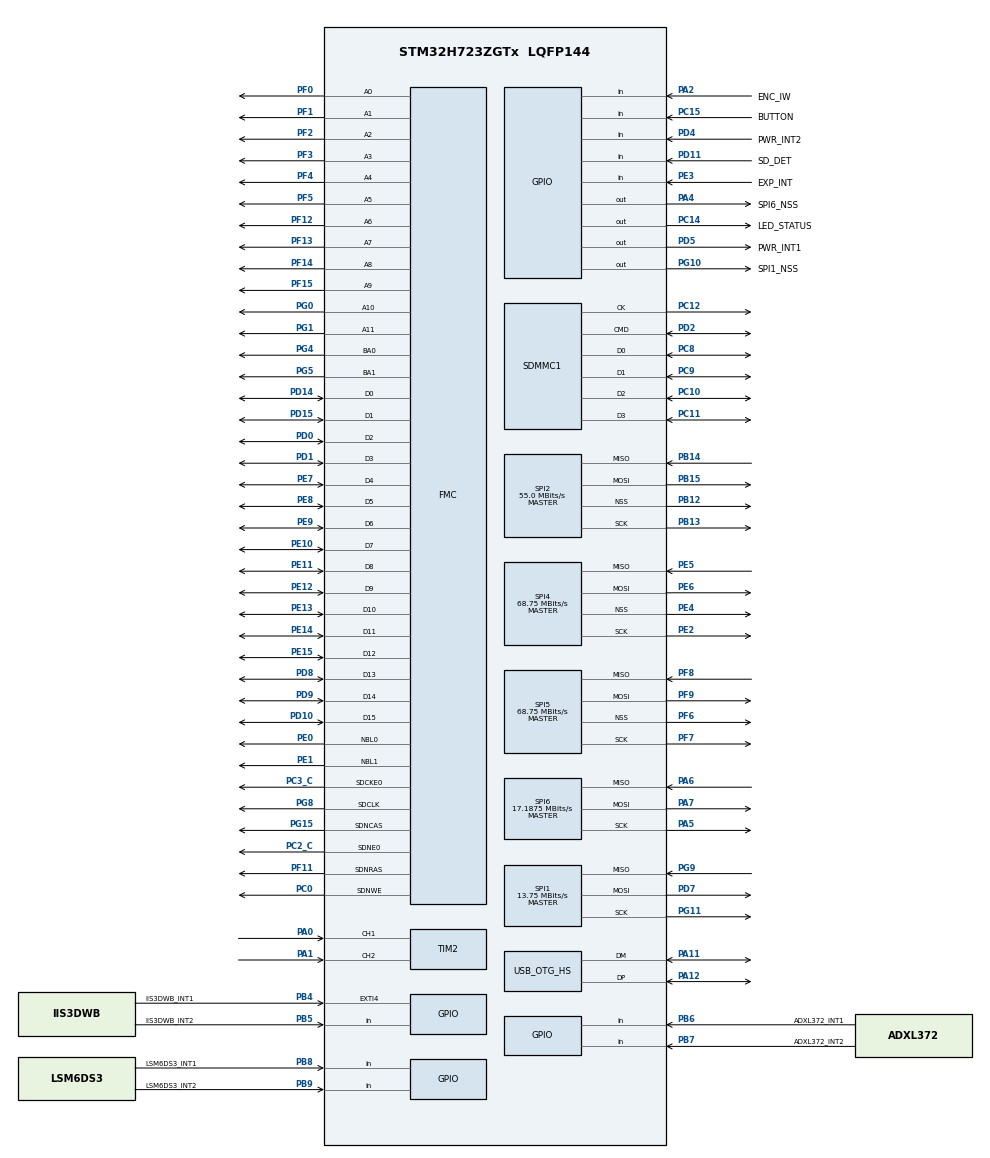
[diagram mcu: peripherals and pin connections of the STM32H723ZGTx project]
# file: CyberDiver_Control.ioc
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FATFS.BSP.number=1
FATFS.USE_DMA_CODE_SD=1
FATFS0.BSP.STBoard=false
FATFS0.BSP.api=Unknown
FATFS0.BSP.instance=PD11
FATFS0.BSP.ip=GPIO
FATFS0.BSP.mode=Input
FATFS0.BSP.name=Detect_SDIO
FATFS0.BSP.solution=PD11
FMC.CASLatency1=FMC_SDRAM_CAS_LATENCY_2
FMC.ColumnBitsNumber1=FMC_SDRAM_COLUMN_BITS_NUM_9
FMC.ExitSelfRefreshDelay1=8
FMC.LoadToActiveDelay1=2
FMC.RCDDelay1=2
FMC.RPDelay1=2
FMC.RPDelay2=2
FMC.ReadBurst1=FMC_SDRAM_RBURST_ENABLE
FMC.ReadBurst2=FMC_SDRAM_RBURST_ENABLE
FMC.ReadPipeDelay1=FMC_SDRAM_RPIPE_DELAY_2
FMC.ReadPipeDelay2=FMC_SDRAM_RPIPE_DELAY_2
FMC.RowCycleDelay1=6
FMC.RowCycleDelay2=6
FMC.SDClockPeriod1=FMC_SDRAM_CLOCK_PERIOD_2
FMC.SDClockPeriod2=FMC_SDRAM_CLOCK_PERIOD_2
FMC.SelfRefreshTime1=5
FMC.WriteRecoveryTime1=3
Mcu.Family=STM32H7
Mcu.Name=STM32H723ZGTx
Mcu.Package=LQFP144
NVIC.EXTI4_IRQn=true\:1\:1\:true\:false\:true\:true\:true\:false
NVIC.OTG_HS_EP1_IN_IRQn=true\:1\:1\:true\:false\:true\:true\:true\:true
NVIC.OTG_HS_EP1_OUT_IRQn=true\:1\:1\:true\:false\:true\:true\:true\:true
NVIC.OTG_HS_IRQn=true\:1\:1\:true\:false\:true\:false\:true\:true
NVIC.PriorityGroup=NVIC_PRIORITYGROUP_2
NVIC.SDMMC1_IRQn=true\:2\:2\:true\:false\:true\:true\:true\:true
NVIC.TIM3_IRQn=true\:0\:0\:false\:false\:true\:true\:true\:true
PA0.Signal=S_TIM2_CH1_ETR
PA1.Signal=S_TIM2_CH2
PA11.Mode=Device_Only_FS
PA11.Signal=USB_OTG_HS_DM
PA12.Mode=Device_Only_FS
PA12.Signal=USB_OTG_HS_DP
PA13(JTMS/SWDIO).Mode=Trace_Asynchronous_SW
PA13(JTMS/SWDIO).Signal=DEBUG_JTMS-SWDIO
PA14(JTCK/SWCLK).Mode=Trace_Asynchronous_SW
PA14(JTCK/SWCLK).Signal=DEBUG_JTCK-SWCLK
PA2.GPIO_Label=ENC_IW
PA2.Signal=GPIO_Input
PA4.GPIO_Label=SPI6_NSS
PA4.GPIO_Speed=GPIO_SPEED_FREQ_VERY_HIGH
PA4.PinState=GPIO_PIN_SET
PA4.Signal=GPIO_Output
PA5.Mode=Full_Duplex_Master
PA5.Signal=SPI6_SCK
PA6.Mode=Full_Duplex_Master
PA6.Signal=SPI6_MISO
PA7.Mode=Full_Duplex_Master
PA7.Signal=SPI6_MOSI
PB12.Mode=NSS_Signal_Hard_Output
PB12.Signal=SPI2_NSS
PB13.Mode=Full_Duplex_Master
PB13.Signal=SPI2_SCK
PB14.Mode=Full_Duplex_Master
PB14.Signal=SPI2_MISO
PB15.Mode=Full_Duplex_Master
PB15.Signal=SPI2_MOSI
PB3(JTDO/TRACESWO).Mode=Trace_Asynchronous_SW
PB3(JTDO/TRACESWO).Signal=DEBUG_JTDO-SWO
PB4(NJTRST).GPIO_Label=IIS3DWB_INT1
PB4(NJTRST).Signal=GPXTI4
PB5.GPIO_Label=IIS3DWB_INT2
PB5.Signal=GPIO_Input
PB6.GPIO_Label=ADXL372_INT1
PB6.Signal=GPIO_Input
PB7.GPIO_Label=ADXL372_INT2
PB7.Signal=GPIO_Input
PB8.GPIO_Label=LSM6DS3_INT1
PB8.Signal=GPIO_Input
PB9.GPIO_Label=LSM6DS3_INT2
PB9.Signal=GPIO_Input
PC0.Signal=FMC_SDNWE
PC10.Mode=SD_4_bits_Wide_bus
PC10.Signal=SDMMC1_D2
PC11.Mode=SD_4_bits_Wide_bus
PC11.Signal=SDMMC1_D3
PC12.Mode=SD_4_bits_Wide_bus
PC12.Signal=SDMMC1_CK
PC14-OSC32_IN.GPIO_Label=LED_STATUS
PC14-OSC32_IN.Signal=GPIO_Output
PC15-OSC32_OUT.GPIO_Label=BUTTON
PC15-OSC32_OUT.Signal=GPIO_Input
PC2_C.Mode=SdramChipSelect1_1
PC2_C.Signal=FMC_SDNE0
PC3_C.Mode=SdramChipSelect1_1
PC3_C.Signal=FMC_SDCKE0
PC8.Mode=SD_4_bits_Wide_bus
PC8.Signal=SDMMC1_D0
PC9.Mode=SD_4_bits_Wide_bus
PC9.Signal=SDMMC1_D1
PD0.Signal=FMC_D2_DA2
PD1.Signal=FMC_D3_DA3
PD10.Signal=FMC_D15_DA15
PD11.GPIO_Label=SD_DET
PD11.Signal=GPIO_Input
PD14.Signal=FMC_D0_DA0
PD15.Signal=FMC_D1_DA1
PD2.Mode=SD_4_bits_Wide_bus
PD2.Signal=SDMMC1_CMD
PD4.GPIO_Label=PWR_INT2
PD4.Signal=GPIO_Input
PD5.GPIO_Label=PWR_INT1
PD5.GPIO_Speed=GPIO_SPEED_FREQ_VERY_HIGH
PD5.Signal=GPIO_Output
PD7.Mode=Full_Duplex_Master
PD7.Signal=SPI1_MOSI
PD8.Signal=FMC_D13_DA13
PD9.Signal=FMC_D14_DA14
PE0.Signal=FMC_NBL0
PE1.Signal=FMC_NBL1
PE10.Signal=FMC_D7_DA7
PE11.Signal=FMC_D8_DA8
PE12.Signal=FMC_D9_DA9
PE13.Signal=FMC_D10_DA10
PE14.Signal=FMC_D11_DA11
PE15.Signal=FMC_D12_DA12
PE2.Mode=Full_Duplex_Master
PE2.Signal=SPI4_SCK
PE3.GPIO_Label=EXP_INT
PE3.Signal=GPIO_Input
PE4.Mode=NSS_Signal_Hard_Output
PE4.Signal=SPI4_NSS
PE5.Mode=Full_Duplex_Master
PE5.Signal=SPI4_MISO
PE6.Mode=Full_Duplex_Master
PE6.Signal=SPI4_MOSI
PE7.Signal=FMC_D4_DA4
PE8.Signal=FMC_D5_DA5
PE9.Signal=FMC_D6_DA6
PF0.Signal=FMC_A0
PF1.Signal=FMC_A1
PF11.Signal=FMC_SDNRAS
PF12.Signal=FMC_A6
PF13.Signal=FMC_A7
PF14.Signal=FMC_A8
PF15.Signal=FMC_A9
PF2.Signal=FMC_A2
PF3.Signal=FMC_A3
PF4.Signal=FMC_A4
PF5.Signal=FMC_A5
PF6.Mode=NSS_Signal_Hard_Output
PF6.Signal=SPI5_NSS
PF7.Mode=Full_Duplex_Master
PF7.Signal=SPI5_SCK
PF8.Mode=Full_Duplex_Master
PF8.Signal=SPI5_MISO
PF9.Mode=Full_Duplex_Master
PF9.Signal=SPI5_MOSI
PG0.Signal=FMC_A10
PG1.Signal=FMC_A11
PG10.GPIO_Label=SPI1_NSS
PG10.GPIO_Speed=GPIO_SPEED_FREQ_VERY_HIGH
PG10.PinState=GPIO_PIN_SET
PG10.Signal=GPIO_Output
PG11.Mode=Full_Duplex_Master
PG11.Signal=SPI1_SCK
PG15.Signal=FMC_SDNCAS
PG4.Signal=FMC_A14_BA0
PG5.Signal=FMC_A15_BA1
PG8.Signal=FMC_SDCLK
PG9.Mode=Full_Duplex_Master
PG9.Signal=SPI1_MISO
PH0-OSC_IN.Mode=HSE-External-Oscillator
PH0-OSC_IN.Signal=RCC_OSC_IN
PH1-OSC_OUT.Mode=HSE-External-Oscillator
PH1-OSC_OUT.Signal=RCC_OSC_OUT
ProjectManager.HeapSize=0x400
ProjectManager.StackSize=0x800
ProjectManager.TargetToolchain=STM32CubeIDE
RCC.ADCFreq_Value=200000000
RCC.APB1Freq_Value=137500000
RCC.APB2Freq_Value=137500000
RCC.APB3Freq_Value=137500000
RCC.APB4Freq_Value=137500000
RCC.CortexFreq_Value=550000000
RCC.D1PPRE=RCC_APB3_DIV2
RCC.D2PPRE1=RCC_APB1_DIV2
RCC.D2PPRE2=RCC_APB2_DIV2
RCC.D3PPRE=RCC_APB4_DIV2
RCC.DIVM1=3
RCC.DIVM2=12
RCC.DIVN1=68
RCC.DIVN2=200
RCC.DIVP1=1
RCC.DIVQ1=5
RCC.FMCCLockSelection=RCC_FMCCLKSOURCE_PLL2
RCC.HCLKFreq_Value=275000000
RCC.HPRE=RCC_HCLK_DIV2
RCC.HSE_VALUE=24000000
RCC.PLL2FRACN=0
RCC.PLL3FRACN=0
RCC.PLLFRACN=6144
RCC.PLLSourceVirtual=RCC_PLLSOURCE_HSE
RCC.SYSCLKFreq_VALUE=550000000
RCC.SYSCLKSource=RCC_SYSCLKSOURCE_PLLCLK
RCC.USBCLockSelection=RCC_USBCLKSOURCE_HSI48
RCC.USBFreq_Value=48000000
SDMMC1.ClockDiv=4
SH.FMC_A0.0=FMC_A0,12b-sda1
SH.FMC_A1.0=FMC_A1,12b-sda1
SH.FMC_A10.0=FMC_A10,12b-sda1
SH.FMC_A11.0=FMC_A11,12b-sda1
SH.FMC_A14_BA0.0=FMC_BA0,FourSdramBanks1
SH.FMC_A15_BA1.0=FMC_BA1,FourSdramBanks1
SH.FMC_A2.0=FMC_A2,12b-sda1
SH.FMC_A3.0=FMC_A3,12b-sda1
SH.FMC_A4.0=FMC_A4,12b-sda1
SH.FMC_A5.0=FMC_A5,12b-sda1
SH.FMC_A6.0=FMC_A6,12b-sda1
SH.FMC_A7.0=FMC_A7,12b-sda1
SH.FMC_A8.0=FMC_A8,12b-sda1
SH.FMC_A9.0=FMC_A9,12b-sda1
SH.FMC_D0_DA0.0=FMC_D0,sd-16b-d1
SH.FMC_D10_DA10.0=FMC_D10,sd-16b-d1
SH.FMC_D11_DA11.0=FMC_D11,sd-16b-d1
SH.FMC_D12_DA12.0=FMC_D12,sd-16b-d1
SH.FMC_D13_DA13.0=FMC_D13,sd-16b-d1
SH.FMC_D14_DA14.0=FMC_D14,sd-16b-d1
SH.FMC_D15_DA15.0=FMC_D15,sd-16b-d1
SH.FMC_D1_DA1.0=FMC_D1,sd-16b-d1
SH.FMC_D2_DA2.0=FMC_D2,sd-16b-d1
SH.FMC_D3_DA3.0=FMC_D3,sd-16b-d1
SH.FMC_D4_DA4.0=FMC_D4,sd-16b-d1
SH.FMC_D5_DA5.0=FMC_D5,sd-16b-d1
SH.FMC_D6_DA6.0=FMC_D6,sd-16b-d1
SH.FMC_D7_DA7.0=FMC_D7,sd-16b-d1
SH.FMC_D8_DA8.0=FMC_D8,sd-16b-d1
SH.FMC_D9_DA9.0=FMC_D9,sd-16b-d1
SH.FMC_NBL0.0=FMC_NBL0,Sd2ByteEnable1
SH.FMC_NBL1.0=FMC_NBL1,Sd2ByteEnable1
SH.FMC_SDCLK.0=FMC_SDCLK,12b-sda1
SH.FMC_SDNCAS.0=FMC_SDNCAS,12b-sda1
SH.FMC_SDNRAS.0=FMC_SDNRAS,12b-sda1
SH.FMC_SDNWE.0=FMC_SDNWE,12b-sda1
SH.S_TIM2_CH1_ETR.0=TIM2_CH1,Encoder_Interface
SH.S_TIM2_CH2.0=TIM2_CH2,Encoder_Interface
SPI1.BaudRatePrescaler=SPI_BAUDRATEPRESCALER_8
SPI1.CalculateBaudRate=13.75 MBits/s
SPI1.DataSize=SPI_DATASIZE_8BIT
SPI1.Direction=SPI_DIRECTION_2LINES
SPI1.Mode=SPI_MODE_MASTER
SPI1.NSSPMode=SPI_NSS_PULSE_DISABLE
SPI1.VirtualType=VM_MASTER
SPI2.CalculateBaudRate=55.0 MBits/s
SPI2.Direction=SPI_DIRECTION_2LINES
SPI2.Mode=SPI_MODE_MASTER
SPI2.VirtualNSS=VM_NSSHARD
SPI2.VirtualType=VM_MASTER
SPI4.BaudRatePrescaler=SPI_BAUDRATEPRESCALER_2
SPI4.CalculateBaudRate=68.75 MBits/s
SPI4.Direction=SPI_DIRECTION_2LINES
SPI4.Mode=SPI_MODE_MASTER
SPI4.VirtualNSS=VM_NSSHARD
SPI4.VirtualType=VM_MASTER
SPI5.CalculateBaudRate=68.75 MBits/s
SPI5.Direction=SPI_DIRECTION_2LINES
SPI5.Mode=SPI_MODE_MASTER
SPI5.VirtualNSS=VM_NSSHARD
SPI5.VirtualType=VM_MASTER
SPI6.BaudRatePrescaler=SPI_BAUDRATEPRESCALER_8
SPI6.CalculateBaudRate=17.1875 MBits/s
SPI6.DataSize=SPI_DATASIZE_8BIT
SPI6.Direction=SPI_DIRECTION_2LINES
SPI6.Mode=SPI_MODE_MASTER
SPI6.NSSPMode=SPI_NSS_PULSE_DISABLE
SPI6.VirtualType=VM_MASTER
TIM2.EncoderMode=TIM_ENCODERMODE_TI12
TIM3.Period=99
TIM3.Prescaler=274
TIM5.Prescaler=274
USB_DEVICE.CLASS_NAME_HS=CDC
USB_DEVICE.PRODUCT_STRING_CDC_HS=CyberDiver
USB_DEVICE.USBD_LPM_ENABLED=0
USB_DEVICE.USBD_SELF_POWERED=0
USB_DEVICE.VirtualMode=Cdc
USB_DEVICE.VirtualModeHS=Cdc_HS
USB_OTG_HS.VirtualMode-Device_Only_FS=Device_Only_FS
VP_FATFS_VS_SDIO.Mode=SDIO
VP_MEMORYMAP_VS_MEMORYMAP.Mode=CurAppReg
VP_TIM3_VS_ClockSourceINT.Mode=Internal
VP_TIM5_VS_ClockSourceINT.Mode=Internal
VP_USB_DEVICE_VS_USB_DEVICE_CDC_HS.Mode=CDC_HS
board=custom

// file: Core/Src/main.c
/* USER CODE BEGIN Header */
/**
  ******************************************************************************
  * @file           : main.c
  * @brief          : Main program body
  ******************************************************************************
  * @attention
  *
  * Copyright (c) 2024 STMicroelectronics.
  * All rights reserved.
  *
  * This software is licensed under terms that can be found in the LICENSE file
  * in the root directory of this software component.
  * If no LICENSE file comes with this software, it is provided AS-IS.
  *
  ******************************************************************************
  */
/* USER CODE END Header */
#include "main.h"
#include "fatfs.h"
#include "usb_device.h"

/* USER CODE BEGIN Includes */
#include "cyber_diver.h"
/* USER CODE END Includes */

SD_HandleTypeDef hsd1;

SPI_HandleTypeDef hspi1;
SPI_HandleTypeDef hspi2;
SPI_HandleTypeDef hspi4;
SPI_HandleTypeDef hspi5;
SPI_HandleTypeDef hspi6;

TIM_HandleTypeDef htim2;
TIM_HandleTypeDef htim3;
TIM_HandleTypeDef htim5;

SDRAM_HandleTypeDef hsdram1;

/* USER CODE BEGIN PV */
CyberDiver cd;
/* USER CODE END PV */

void SystemClock_Config(void);
static void MX_GPIO_Init(void);
static void MX_FMC_Init(void);
static void MX_SPI1_Init(void);
static void MX_SPI2_Init(void);
static void MX_SPI4_Init(void);
static void MX_SPI5_Init(void);
static void MX_SPI6_Init(void);
static void MX_TIM2_Init(void);
static void MX_TIM5_Init(void);
static void MX_TIM3_Init(void);
static void MX_SDMMC1_SD_Init(void);

/* USER CODE BEGIN 0 */

void FMC_Init()
{
	/*
	 * This SDRAM initialization code comes from the following ST support article:
	 * https://community.st.com/t5/stm32-mcus/how-to-set-up-the-fmc-peripheral-to-interface-with-the-sdram/ta-p/49457
	 */

	FMC_SDRAM_CommandTypeDef Command;
	HAL_StatusTypeDef status;
	(void)status;

	/* Step 1 and Step 2 already done in HAL_SDRAM_Init() */

	/* Step 3: Configure a clock configuration enable command */
	Command.CommandMode            = FMC_SDRAM_CMD_CLK_ENABLE;  /* Set MODE bits to "001" */
	Command.CommandTarget          = FMC_SDRAM_CMD_TARGET_BANK1;  /* configure the Target Bank bits */
	Command.AutoRefreshNumber      = 1;
	Command.ModeRegisterDefinition = 0;
	status = HAL_SDRAM_SendCommand(&hsdram1, &Command, 0xfff);

	/* Step 4: Insert 100 us minimum delay - Min HAL Delay is 1ms */
	HAL_Delay(1);

	/* Step 5: Configure a PALL (precharge all) command */
	Command.CommandMode            = FMC_SDRAM_CMD_PALL;  /* Set MODE bits to "010" */
	status = HAL_SDRAM_SendCommand(&hsdram1, &Command, 0xfff);

	/* Step 6: Configure an Auto Refresh command */
	Command.CommandMode            = FMC_SDRAM_CMD_AUTOREFRESH_MODE;  /* Set MODE bits to "011" */
	Command.AutoRefreshNumber      = 2;
	status = HAL_SDRAM_SendCommand(&hsdram1, &Command, 0xfff);

	/* Step 7: Program the external memory mode register */
	Command.CommandMode            = FMC_SDRAM_CMD_LOAD_MODE;  /*set the MODE bits to "100" */
	Command.ModeRegisterDefinition =  (uint32_t)0 | 0<<3 | 2<<4 | 0<<7 | 1<<9;
	status = HAL_SDRAM_SendCommand(&hsdram1, &Command, 0xfff);

	/* Step 8: Set the refresh rate counter - refer to section SDRAM refresh timer register in RM0455 */
	/* Set the device refresh rate
	* COUNT = [(SDRAM self refresh time / number of row) x  SDRAM CLK] – 20
			= [(64ms/4096) * 100MHz] - 20 = 1562.5 - 20 ~ 1542 */
	status = HAL_SDRAM_ProgramRefreshRate(&hsdram1, 1542);
}

void HAL_GPIO_EXTI_Callback(uint16_t GPIO_Pin)
{
	/* read the accelerometer */
	IIS3DWB_ReadAcceleration(&(cd.accelerometer));
}

void HAL_TIM_PeriodElapsedCallback(TIM_HandleTypeDef* htim)
{
	/* update the time-critical parts of the CyberDiver */
    CyberDiver_TimerUpdate(&cd);
}

/* USER CODE END 0 */

int main(void)
{

  /* MCU Configuration--------------------------------------------------------*/

  /* Reset of all peripherals, Initializes the Flash interface and the Systick. */
  HAL_Init();

  /* Configure the system clock */
  SystemClock_Config();

  /* Initialize all configured peripherals */
  MX_GPIO_Init();
  MX_FMC_Init();
  MX_SPI1_Init();
  MX_SPI2_Init();
  MX_SPI4_Init();
  MX_SPI5_Init();
  MX_SPI6_Init();
  MX_TIM2_Init();
  MX_USB_DEVICE_Init();
  MX_TIM5_Init();
  MX_TIM3_Init();
  MX_SDMMC1_SD_Init();
  MX_FATFS_Init();
  /* USER CODE BEGIN 2 */

  FMC_Init();  /* Final initialization of SDRAM */

  /* USER CODE END 2 */

  /* Infinite loop */
  /* USER CODE BEGIN WHILE */

  HAL_TIM_Base_Start(&htim5);  /* for general time-keeping */

  CyberDiver_Init(&cd,
		  &(TIM5->CNT),
		  &htim3,
		  &htim2,

		  &hspi1,
		  SPI1_NSS_GPIO_Port,
		  SPI1_NSS_Pin,
		  PWR_INT1_GPIO_Port,
		  PWR_INT1_Pin,
		  PWR_INT2_GPIO_Port,
		  PWR_INT2_Pin,

		  &hspi6,
		  SPI6_NSS_GPIO_Port,
		  SPI6_NSS_Pin,
		  IIS3DWB_INT1_GPIO_Port,
		  IIS3DWB_INT1_Pin,
		  IIS3DWB_INT2_GPIO_Port,
		  IIS3DWB_INT2_Pin,

		  LED_STATUS_GPIO_Port,
		  LED_STATUS_Pin,
		  BUTTON_GPIO_Port,
		  BUTTON_Pin);

  while (1)
  {

	CyberDiver_Loop(&cd);

    /* USER CODE END WHILE */

  }
}

void SystemClock_Config(void)
{
  RCC_OscInitTypeDef RCC_OscInitStruct = {0};
  RCC_ClkInitTypeDef RCC_ClkInitStruct = {0};

  /** Supply configuration update enable
  */
  HAL_PWREx_ConfigSupply(PWR_LDO_SUPPLY);

  /** Configure the main internal regulator output voltage
  */
  __HAL_PWR_VOLTAGESCALING_CONFIG(PWR_REGULATOR_VOLTAGE_SCALE0);

  while(!__HAL_PWR_GET_FLAG(PWR_FLAG_VOSRDY)) {}

  /** Initializes the RCC Oscillators according to the specified parameters
  * in the RCC_OscInitTypeDef structure.
  */
  RCC_OscInitStruct.OscillatorType = RCC_OSCILLATORTYPE_HSI48|RCC_OSCILLATORTYPE_HSE;
  RCC_OscInitStruct.HSEState = RCC_HSE_ON;
  RCC_OscInitStruct.HSI48State = RCC_HSI48_ON;
  RCC_OscInitStruct.PLL.PLLState = RCC_PLL_ON;
  RCC_OscInitStruct.PLL.PLLSource = RCC_PLLSOURCE_HSE;
  RCC_OscInitStruct.PLL.PLLM = 3;
  RCC_OscInitStruct.PLL.PLLN = 68;
  RCC_OscInitStruct.PLL.PLLP = 1;
  RCC_OscInitStruct.PLL.PLLQ = 5;
  RCC_OscInitStruct.PLL.PLLR = 2;
  RCC_OscInitStruct.PLL.PLLRGE = RCC_PLL1VCIRANGE_3;
  RCC_OscInitStruct.PLL.PLLVCOSEL = RCC_PLL1VCOWIDE;
  RCC_OscInitStruct.PLL.PLLFRACN = 6144;
  if (HAL_RCC_OscConfig(&RCC_OscInitStruct) != HAL_OK)
  {
    Error_Handler();
  }

  /** Initializes the CPU, AHB and APB buses clocks
  */
  RCC_ClkInitStruct.ClockType = RCC_CLOCKTYPE_HCLK|RCC_CLOCKTYPE_SYSCLK
                              |RCC_CLOCKTYPE_PCLK1|RCC_CLOCKTYPE_PCLK2
                              |RCC_CLOCKTYPE_D3PCLK1|RCC_CLOCKTYPE_D1PCLK1;
  RCC_ClkInitStruct.SYSCLKSource = RCC_SYSCLKSOURCE_PLLCLK;
  RCC_ClkInitStruct.SYSCLKDivider = RCC_SYSCLK_DIV1;
  RCC_ClkInitStruct.AHBCLKDivider = RCC_HCLK_DIV2;
  RCC_ClkInitStruct.APB3CLKDivider = RCC_APB3_DIV2;
  RCC_ClkInitStruct.APB1CLKDivider = RCC_APB1_DIV2;
  RCC_ClkInitStruct.APB2CLKDivider = RCC_APB2_DIV2;
  RCC_ClkInitStruct.APB4CLKDivider = RCC_APB4_DIV2;

  if (HAL_RCC_ClockConfig(&RCC_ClkInitStruct, FLASH_LATENCY_3) != HAL_OK)
  {
    Error_Handler();
  }
}

static void MX_SDMMC1_SD_Init(void)
{

  hsd1.Instance = SDMMC1;
  hsd1.Init.ClockEdge = SDMMC_CLOCK_EDGE_RISING;
  hsd1.Init.ClockPowerSave = SDMMC_CLOCK_POWER_SAVE_DISABLE;
  hsd1.Init.BusWide = SDMMC_BUS_WIDE_4B;
  hsd1.Init.HardwareFlowControl = SDMMC_HARDWARE_FLOW_CONTROL_DISABLE;
  hsd1.Init.ClockDiv = 4;

}

static void MX_SPI1_Init(void)
{

  /* SPI1 parameter configuration*/
  hspi1.Instance = SPI1;
  hspi1.Init.Mode = SPI_MODE_MASTER;
  hspi1.Init.Direction = SPI_DIRECTION_2LINES;
  hspi1.Init.DataSize = SPI_DATASIZE_8BIT;
  hspi1.Init.CLKPolarity = SPI_POLARITY_LOW;
  hspi1.Init.CLKPhase = SPI_PHASE_1EDGE;
  hspi1.Init.NSS = SPI_NSS_SOFT;
  hspi1.Init.BaudRatePrescaler = SPI_BAUDRATEPRESCALER_8;
  hspi1.Init.FirstBit = SPI_FIRSTBIT_MSB;
  hspi1.Init.TIMode = SPI_TIMODE_DISABLE;
  hspi1.Init.CRCCalculation = SPI_CRCCALCULATION_DISABLE;
  hspi1.Init.CRCPolynomial = 0x0;
  hspi1.Init.NSSPMode = SPI_NSS_PULSE_DISABLE;
  hspi1.Init.NSSPolarity = SPI_NSS_POLARITY_LOW;
  hspi1.Init.FifoThreshold = SPI_FIFO_THRESHOLD_01DATA;
  hspi1.Init.TxCRCInitializationPattern = SPI_CRC_INITIALIZATION_ALL_ZERO_PATTERN;
  hspi1.Init.RxCRCInitializationPattern = SPI_CRC_INITIALIZATION_ALL_ZERO_PATTERN;
  hspi1.Init.MasterSSIdleness = SPI_MASTER_SS_IDLENESS_00CYCLE;
  hspi1.Init.MasterInterDataIdleness = SPI_MASTER_INTERDATA_IDLENESS_00CYCLE;
  hspi1.Init.MasterReceiverAutoSusp = SPI_MASTER_RX_AUTOSUSP_DISABLE;
  hspi1.Init.MasterKeepIOState = SPI_MASTER_KEEP_IO_STATE_DISABLE;
  hspi1.Init.IOSwap = SPI_IO_SWAP_DISABLE;
  if (HAL_SPI_Init(&hspi1) != HAL_OK)
  {
    Error_Handler();
  }

}

static void MX_SPI2_Init(void)
{

  /* SPI2 parameter configuration*/
  hspi2.Instance = SPI2;
  hspi2.Init.Mode = SPI_MODE_MASTER;
  hspi2.Init.Direction = SPI_DIRECTION_2LINES;
  hspi2.Init.DataSize = SPI_DATASIZE_4BIT;
  hspi2.Init.CLKPolarity = SPI_POLARITY_LOW;
  hspi2.Init.CLKPhase = SPI_PHASE_1EDGE;
  hspi2.Init.NSS = SPI_NSS_HARD_OUTPUT;
  hspi2.Init.BaudRatePrescaler = SPI_BAUDRATEPRESCALER_2;
  hspi2.Init.FirstBit = SPI_FIRSTBIT_MSB;
  hspi2.Init.TIMode = SPI_TIMODE_DISABLE;
  hspi2.Init.CRCCalculation = SPI_CRCCALCULATION_DISABLE;
  hspi2.Init.CRCPolynomial = 0x0;
  hspi2.Init.NSSPMode = SPI_NSS_PULSE_ENABLE;
  hspi2.Init.NSSPolarity = SPI_NSS_POLARITY_LOW;
  hspi2.Init.FifoThreshold = SPI_FIFO_THRESHOLD_01DATA;
  hspi2.Init.TxCRCInitializationPattern = SPI_CRC_INITIALIZATION_ALL_ZERO_PATTERN;
  hspi2.Init.RxCRCInitializationPattern = SPI_CRC_INITIALIZATION_ALL_ZERO_PATTERN;
  hspi2.Init.MasterSSIdleness = SPI_MASTER_SS_IDLENESS_00CYCLE;
  hspi2.Init.MasterInterDataIdleness = SPI_MASTER_INTERDATA_IDLENESS_00CYCLE;
  hspi2.Init.MasterReceiverAutoSusp = SPI_MASTER_RX_AUTOSUSP_DISABLE;
  hspi2.Init.MasterKeepIOState = SPI_MASTER_KEEP_IO_STATE_DISABLE;
  hspi2.Init.IOSwap = SPI_IO_SWAP_DISABLE;
  if (HAL_SPI_Init(&hspi2) != HAL_OK)
  {
    Error_Handler();
  }

}

static void MX_SPI4_Init(void)
{

  /* SPI4 parameter configuration*/
  hspi4.Instance = SPI4;
  hspi4.Init.Mode = SPI_MODE_MASTER;
  hspi4.Init.Direction = SPI_DIRECTION_2LINES;
  hspi4.Init.DataSize = SPI_DATASIZE_4BIT;
  hspi4.Init.CLKPolarity = SPI_POLARITY_LOW;
  hspi4.Init.CLKPhase = SPI_PHASE_1EDGE;
  hspi4.Init.NSS = SPI_NSS_HARD_OUTPUT;
  hspi4.Init.BaudRatePrescaler = SPI_BAUDRATEPRESCALER_2;
  hspi4.Init.FirstBit = SPI_FIRSTBIT_MSB;
  hspi4.Init.TIMode = SPI_TIMODE_DISABLE;
  hspi4.Init.CRCCalculation = SPI_CRCCALCULATION_DISABLE;
  hspi4.Init.CRCPolynomial = 0x0;
  hspi4.Init.NSSPMode = SPI_NSS_PULSE_ENABLE;
  hspi4.Init.NSSPolarity = SPI_NSS_POLARITY_LOW;
  hspi4.Init.FifoThreshold = SPI_FIFO_THRESHOLD_01DATA;
  hspi4.Init.TxCRCInitializationPattern = SPI_CRC_INITIALIZATION_ALL_ZERO_PATTERN;
  hspi4.Init.RxCRCInitializationPattern = SPI_CRC_INITIALIZATION_ALL_ZERO_PATTERN;
  hspi4.Init.MasterSSIdleness = SPI_MASTER_SS_IDLENESS_00CYCLE;
  hspi4.Init.MasterInterDataIdleness = SPI_MASTER_INTERDATA_IDLENESS_00CYCLE;
  hspi4.Init.MasterReceiverAutoSusp = SPI_MASTER_RX_AUTOSUSP_DISABLE;
  hspi4.Init.MasterKeepIOState = SPI_MASTER_KEEP_IO_STATE_DISABLE;
  hspi4.Init.IOSwap = SPI_IO_SWAP_DISABLE;
  if (HAL_SPI_Init(&hspi4) != HAL_OK)
  {
    Error_Handler();
  }

}

static void MX_SPI5_Init(void)
{

  /* SPI5 parameter configuration*/
  hspi5.Instance = SPI5;
  hspi5.Init.Mode = SPI_MODE_MASTER;
  hspi5.Init.Direction = SPI_DIRECTION_2LINES;
  hspi5.Init.DataSize = SPI_DATASIZE_4BIT;
  hspi5.Init.CLKPolarity = SPI_POLARITY_LOW;
  hspi5.Init.CLKPhase = SPI_PHASE_1EDGE;
  hspi5.Init.NSS = SPI_NSS_HARD_OUTPUT;
  hspi5.Init.BaudRatePrescaler = SPI_BAUDRATEPRESCALER_2;
  hspi5.Init.FirstBit = SPI_FIRSTBIT_MSB;
  hspi5.Init.TIMode = SPI_TIMODE_DISABLE;
  hspi5.Init.CRCCalculation = SPI_CRCCALCULATION_DISABLE;
  hspi5.Init.CRCPolynomial = 0x0;
  hspi5.Init.NSSPMode = SPI_NSS_PULSE_ENABLE;
  hspi5.Init.NSSPolarity = SPI_NSS_POLARITY_LOW;
  hspi5.Init.FifoThreshold = SPI_FIFO_THRESHOLD_01DATA;
  hspi5.Init.TxCRCInitializationPattern = SPI_CRC_INITIALIZATION_ALL_ZERO_PATTERN;
  hspi5.Init.RxCRCInitializationPattern = SPI_CRC_INITIALIZATION_ALL_ZERO_PATTERN;
  hspi5.Init.MasterSSIdleness = SPI_MASTER_SS_IDLENESS_00CYCLE;
  hspi5.Init.MasterInterDataIdleness = SPI_MASTER_INTERDATA_IDLENESS_00CYCLE;
  hspi5.Init.MasterReceiverAutoSusp = SPI_MASTER_RX_AUTOSUSP_DISABLE;
  hspi5.Init.MasterKeepIOState = SPI_MASTER_KEEP_IO_STATE_DISABLE;
  hspi5.Init.IOSwap = SPI_IO_SWAP_DISABLE;
  if (HAL_SPI_Init(&hspi5) != HAL_OK)
  {
    Error_Handler();
  }

}

static void MX_SPI6_Init(void)
{

  /* SPI6 parameter configuration*/
  hspi6.Instance = SPI6;
  hspi6.Init.Mode = SPI_MODE_MASTER;
  hspi6.Init.Direction = SPI_DIRECTION_2LINES;
  hspi6.Init.DataSize = SPI_DATASIZE_8BIT;
  hspi6.Init.CLKPolarity = SPI_POLARITY_LOW;
  hspi6.Init.CLKPhase = SPI_PHASE_1EDGE;
  hspi6.Init.NSS = SPI_NSS_SOFT;
  hspi6.Init.BaudRatePrescaler = SPI_BAUDRATEPRESCALER_8;
  hspi6.Init.FirstBit = SPI_FIRSTBIT_MSB;
  hspi6.Init.TIMode = SPI_TIMODE_DISABLE;
  hspi6.Init.CRCCalculation = SPI_CRCCALCULATION_DISABLE;
  hspi6.Init.CRCPolynomial = 0x0;
  hspi6.Init.NSSPMode = SPI_NSS_PULSE_DISABLE;
  hspi6.Init.NSSPolarity = SPI_NSS_POLARITY_LOW;
  hspi6.Init.FifoThreshold = SPI_FIFO_THRESHOLD_01DATA;
  hspi6.Init.TxCRCInitializationPattern = SPI_CRC_INITIALIZATION_ALL_ZERO_PATTERN;
  hspi6.Init.RxCRCInitializationPattern = SPI_CRC_INITIALIZATION_ALL_ZERO_PATTERN;
  hspi6.Init.MasterSSIdleness = SPI_MASTER_SS_IDLENESS_00CYCLE;
  hspi6.Init.MasterInterDataIdleness = SPI_MASTER_INTERDATA_IDLENESS_00CYCLE;
  hspi6.Init.MasterReceiverAutoSusp = SPI_MASTER_RX_AUTOSUSP_DISABLE;
  hspi6.Init.MasterKeepIOState = SPI_MASTER_KEEP_IO_STATE_DISABLE;
  hspi6.Init.IOSwap = SPI_IO_SWAP_DISABLE;
  if (HAL_SPI_Init(&hspi6) != HAL_OK)
  {
    Error_Handler();
  }

}

static void MX_TIM2_Init(void)
{

  TIM_Encoder_InitTypeDef sConfig = {0};
  TIM_MasterConfigTypeDef sMasterConfig = {0};

  htim2.Instance = TIM2;
  htim2.Init.Prescaler = 0;
  htim2.Init.CounterMode = TIM_COUNTERMODE_UP;
  htim2.Init.Period = 4294967295;
  htim2.Init.ClockDivision = TIM_CLOCKDIVISION_DIV1;
  htim2.Init.AutoReloadPreload = TIM_AUTORELOAD_PRELOAD_DISABLE;
  sConfig.EncoderMode = TIM_ENCODERMODE_TI12;
  sConfig.IC1Polarity = TIM_ICPOLARITY_RISING;
  sConfig.IC1Selection = TIM_ICSELECTION_DIRECTTI;
  sConfig.IC1Prescaler = TIM_ICPSC_DIV1;
  sConfig.IC1Filter = 0;
  sConfig.IC2Polarity = TIM_ICPOLARITY_RISING;
  sConfig.IC2Selection = TIM_ICSELECTION_DIRECTTI;
  sConfig.IC2Prescaler = TIM_ICPSC_DIV1;
  sConfig.IC2Filter = 0;
  if (HAL_TIM_Encoder_Init(&htim2, &sConfig) != HAL_OK)
  {
    Error_Handler();
  }
  sMasterConfig.MasterOutputTrigger = TIM_TRGO_RESET;
  sMasterConfig.MasterSlaveMode = TIM_MASTERSLAVEMODE_DISABLE;
  if (HAL_TIMEx_MasterConfigSynchronization(&htim2, &sMasterConfig) != HAL_OK)
  {
    Error_Handler();
  }

}

static void MX_TIM3_Init(void)
{

  TIM_ClockConfigTypeDef sClockSourceConfig = {0};
  TIM_MasterConfigTypeDef sMasterConfig = {0};

  htim3.Instance = TIM3;
  htim3.Init.Prescaler = 274;
  htim3.Init.CounterMode = TIM_COUNTERMODE_UP;
  htim3.Init.Period = 99;
  htim3.Init.ClockDivision = TIM_CLOCKDIVISION_DIV1;
  htim3.Init.AutoReloadPreload = TIM_AUTORELOAD_PRELOAD_DISABLE;
  if (HAL_TIM_Base_Init(&htim3) != HAL_OK)
  {
    Error_Handler();
  }
  sClockSourceConfig.ClockSource = TIM_CLOCKSOURCE_INTERNAL;
  if (HAL_TIM_ConfigClockSource(&htim3, &sClockSourceConfig) != HAL_OK)
  {
    Error_Handler();
  }
  sMasterConfig.MasterOutputTrigger = TIM_TRGO_RESET;
  sMasterConfig.MasterSlaveMode = TIM_MASTERSLAVEMODE_DISABLE;
  if (HAL_TIMEx_MasterConfigSynchronization(&htim3, &sMasterConfig) != HAL_OK)
  {
    Error_Handler();
  }

}

static void MX_TIM5_Init(void)
{

  TIM_ClockConfigTypeDef sClockSourceConfig = {0};
  TIM_MasterConfigTypeDef sMasterConfig = {0};

  htim5.Instance = TIM5;
  htim5.Init.Prescaler = 274;
  htim5.Init.CounterMode = TIM_COUNTERMODE_UP;
  htim5.Init.Period = 4294967295;
  htim5.Init.ClockDivision = TIM_CLOCKDIVISION_DIV1;
  htim5.Init.AutoReloadPreload = TIM_AUTORELOAD_PRELOAD_DISABLE;
  if (HAL_TIM_Base_Init(&htim5) != HAL_OK)
  {
    Error_Handler();
  }
  sClockSourceConfig.ClockSource = TIM_CLOCKSOURCE_INTERNAL;
  if (HAL_TIM_ConfigClockSource(&htim5, &sClockSourceConfig) != HAL_OK)
  {
    Error_Handler();
  }
  sMasterConfig.MasterOutputTrigger = TIM_TRGO_RESET;
  sMasterConfig.MasterSlaveMode = TIM_MASTERSLAVEMODE_DISABLE;
  if (HAL_TIMEx_MasterConfigSynchronization(&htim5, &sMasterConfig) != HAL_OK)
  {
    Error_Handler();
  }

}

/* FMC initialization function */
static void MX_FMC_Init(void)
{

  FMC_SDRAM_TimingTypeDef SdramTiming = {0};

  /** Perform the SDRAM1 memory initialization sequence
  */
  hsdram1.Instance = FMC_SDRAM_DEVICE;
  /* hsdram1.Init */
  hsdram1.Init.SDBank = FMC_SDRAM_BANK1;
  hsdram1.Init.ColumnBitsNumber = FMC_SDRAM_COLUMN_BITS_NUM_9;
  hsdram1.Init.RowBitsNumber = FMC_SDRAM_ROW_BITS_NUM_12;
  hsdram1.Init.MemoryDataWidth = FMC_SDRAM_MEM_BUS_WIDTH_16;
  hsdram1.Init.InternalBankNumber = FMC_SDRAM_INTERN_BANKS_NUM_4;
  hsdram1.Init.CASLatency = FMC_SDRAM_CAS_LATENCY_2;
  hsdram1.Init.WriteProtection = FMC_SDRAM_WRITE_PROTECTION_DISABLE;
  hsdram1.Init.SDClockPeriod = FMC_SDRAM_CLOCK_PERIOD_2;
  hsdram1.Init.ReadBurst = FMC_SDRAM_RBURST_ENABLE;
  hsdram1.Init.ReadPipeDelay = FMC_SDRAM_RPIPE_DELAY_2;
  /* SdramTiming */
  SdramTiming.LoadToActiveDelay = 2;
  SdramTiming.ExitSelfRefreshDelay = 8;
  SdramTiming.SelfRefreshTime = 5;
  SdramTiming.RowCycleDelay = 6;
  SdramTiming.WriteRecoveryTime = 3;
  SdramTiming.RPDelay = 2;
  SdramTiming.RCDDelay = 2;

  if (HAL_SDRAM_Init(&hsdram1, &SdramTiming) != HAL_OK)
  {
    Error_Handler( );
  }

}

static void MX_GPIO_Init(void)
{
  GPIO_InitTypeDef GPIO_InitStruct = {0};

  /* GPIO Ports Clock Enable */
  __HAL_RCC_GPIOE_CLK_ENABLE();
  __HAL_RCC_GPIOC_CLK_ENABLE();
  __HAL_RCC_GPIOF_CLK_ENABLE();
  __HAL_RCC_GPIOH_CLK_ENABLE();
  __HAL_RCC_GPIOA_CLK_ENABLE();
  __HAL_RCC_GPIOG_CLK_ENABLE();
  __HAL_RCC_GPIOB_CLK_ENABLE();
  __HAL_RCC_GPIOD_CLK_ENABLE();

  /*Configure GPIO pin Output Level */
  HAL_GPIO_WritePin(LED_STATUS_GPIO_Port, LED_STATUS_Pin, GPIO_PIN_RESET);

  /*Configure GPIO pin Output Level */
  HAL_GPIO_WritePin(SPI6_NSS_GPIO_Port, SPI6_NSS_Pin, GPIO_PIN_SET);

  /*Configure GPIO pin Output Level */
  HAL_GPIO_WritePin(PWR_INT1_GPIO_Port, PWR_INT1_Pin, GPIO_PIN_RESET);

  /*Configure GPIO pin Output Level */
  HAL_GPIO_WritePin(SPI1_NSS_GPIO_Port, SPI1_NSS_Pin, GPIO_PIN_SET);

  /*Configure GPIO pin : EXP_INT_Pin */
  GPIO_InitStruct.Pin = EXP_INT_Pin;
  GPIO_InitStruct.Mode = GPIO_MODE_INPUT;
  GPIO_InitStruct.Pull = GPIO_NOPULL;
  HAL_GPIO_Init(EXP_INT_GPIO_Port, &GPIO_InitStruct);

  /*Configure GPIO pin : LED_STATUS_Pin */
  GPIO_InitStruct.Pin = LED_STATUS_Pin;
  GPIO_InitStruct.Mode = GPIO_MODE_OUTPUT_PP;
  GPIO_InitStruct.Pull = GPIO_NOPULL;
  GPIO_InitStruct.Speed = GPIO_SPEED_FREQ_LOW;
  HAL_GPIO_Init(LED_STATUS_GPIO_Port, &GPIO_InitStruct);

  /*Configure GPIO pin : BUTTON_Pin */
  GPIO_InitStruct.Pin = BUTTON_Pin;
  GPIO_InitStruct.Mode = GPIO_MODE_INPUT;
  GPIO_InitStruct.Pull = GPIO_NOPULL;
  HAL_GPIO_Init(BUTTON_GPIO_Port, &GPIO_InitStruct);

  /*Configure GPIO pin : ENC_IW_Pin */
  GPIO_InitStruct.Pin = ENC_IW_Pin;
  GPIO_InitStruct.Mode = GPIO_MODE_INPUT;
  GPIO_InitStruct.Pull = GPIO_NOPULL;
  HAL_GPIO_Init(ENC_IW_GPIO_Port, &GPIO_InitStruct);

  /*Configure GPIO pin : SPI6_NSS_Pin */
  GPIO_InitStruct.Pin = SPI6_NSS_Pin;
  GPIO_InitStruct.Mode = GPIO_MODE_OUTPUT_PP;
  GPIO_InitStruct.Pull = GPIO_NOPULL;
  GPIO_InitStruct.Speed = GPIO_SPEED_FREQ_VERY_HIGH;
  HAL_GPIO_Init(SPI6_NSS_GPIO_Port, &GPIO_InitStruct);

  /*Configure GPIO pins : SD_DET_Pin PWR_INT2_Pin */
  GPIO_InitStruct.Pin = SD_DET_Pin|PWR_INT2_Pin;
  GPIO_InitStruct.Mode = GPIO_MODE_INPUT;
  GPIO_InitStruct.Pull = GPIO_NOPULL;
  HAL_GPIO_Init(GPIOD, &GPIO_InitStruct);

  /*Configure GPIO pin : PWR_INT1_Pin */
  GPIO_InitStruct.Pin = PWR_INT1_Pin;
  GPIO_InitStruct.Mode = GPIO_MODE_OUTPUT_PP;
  GPIO_InitStruct.Pull = GPIO_NOPULL;
  GPIO_InitStruct.Speed = GPIO_SPEED_FREQ_VERY_HIGH;
  HAL_GPIO_Init(PWR_INT1_GPIO_Port, &GPIO_InitStruct);

  /*Configure GPIO pin : SPI1_NSS_Pin */
  GPIO_InitStruct.Pin = SPI1_NSS_Pin;
  GPIO_InitStruct.Mode = GPIO_MODE_OUTPUT_PP;
  GPIO_InitStruct.Pull = GPIO_NOPULL;
  GPIO_InitStruct.Speed = GPIO_SPEED_FREQ_VERY_HIGH;
  HAL_GPIO_Init(SPI1_NSS_GPIO_Port, &GPIO_InitStruct);

  /*Configure GPIO pin : IIS3DWB_INT1_Pin */
  GPIO_InitStruct.Pin = IIS3DWB_INT1_Pin;
  GPIO_InitStruct.Mode = GPIO_MODE_IT_RISING;
  GPIO_InitStruct.Pull = GPIO_NOPULL;
  HAL_GPIO_Init(IIS3DWB_INT1_GPIO_Port, &GPIO_InitStruct);

  /*Configure GPIO pins : IIS3DWB_INT2_Pin ADXL372_INT1_Pin ADXL372_INT2_Pin LSM6DS3_INT1_Pin
                           LSM6DS3_INT2_Pin */
  GPIO_InitStruct.Pin = IIS3DWB_INT2_Pin|ADXL372_INT1_Pin|ADXL372_INT2_Pin|LSM6DS3_INT1_Pin
                          |LSM6DS3_INT2_Pin;
  GPIO_InitStruct.Mode = GPIO_MODE_INPUT;
  GPIO_InitStruct.Pull = GPIO_NOPULL;
  HAL_GPIO_Init(GPIOB, &GPIO_InitStruct);

  /* EXTI interrupt init*/
  HAL_NVIC_SetPriority(EXTI4_IRQn, 1, 1);

}

void Error_Handler(void)
{
  __disable_irq();
  while (1)
  {
  }
}
